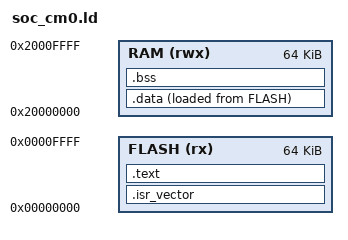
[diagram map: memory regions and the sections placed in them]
/* Framework linker map. Confirm memory sizes before compiling firmware. */
ENTRY(Reset_Handler)

MEMORY
{
    FLASH (rx)  : ORIGIN = 0x00000000, LENGTH = 64K
    RAM   (rwx) : ORIGIN = 0x20000000, LENGTH = 64K
}

SECTIONS
{
    .isr_vector :
    {
        KEEP(*(.isr_vector))
    } > FLASH

    .text :
    {
        *(.text*)
        *(.rodata*)
        KEEP(*(.init))
        KEEP(*(.fini))
    } > FLASH

    .data :
    {
        _sdata = .;
        *(.data*)
        _edata = .;
    } > RAM AT > FLASH
    _sidata = LOADADDR(.data);

    .bss (NOLOAD) :
    {
        _sbss = .;
        *(.bss*)
        *(COMMON)
        _ebss = .;
    } > RAM

    . = ALIGN(8);
    _end = .;
    _estack = ORIGIN(RAM) + LENGTH(RAM);
}
